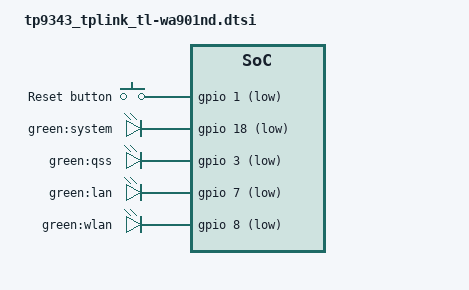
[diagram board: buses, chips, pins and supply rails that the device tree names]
// SPDX-License-Identifier: GPL-2.0-or-later OR MIT

#include "tp9343_tplink_tl-wx.dtsi"

/ {
	aliases {
		led-boot = &led_system;
		led-failsafe = &led_system;
		led-running = &led_system;
		led-upgrade = &led_system;
	};

	keys {
		compatible = "gpio-keys";

		reset {
			label = "Reset button";
			linux,code = <KEY_RESTART>;
			gpios = <&gpio 1 GPIO_ACTIVE_LOW>;
		};
	};

	leds {
		compatible = "gpio-leds";

		led_system: system {
			label = "green:system";
			gpios = <&gpio 18 GPIO_ACTIVE_LOW>;
			default-state = "on";
		};

		qss {
			label = "green:qss";
			gpios = <&gpio 3 GPIO_ACTIVE_LOW>;
		};

		lan {
			label = "green:lan";
			gpios = <&gpio 7 GPIO_ACTIVE_LOW>;
		};

		wlan {
			label = "green:wlan";
			gpios = <&gpio 8 GPIO_ACTIVE_LOW>;
			linux,default-trigger = "phy0tpt";
		};
	};
};

&eth1 {
	compatible = "syscon", "simple-mfd";
};
